# 3061MNNIC8 register map
File version: 1.0
Registers are 32-bit, access per field, reset 0x0 unless marked. A register's access mark holds for its fields unless they carry their own. Offsets are from the block's base; [hi:lo] are bit positions; {n}, {i} and the like mark numbered series.

## CAPM_COMM — CAPM_COMM peripheral interface
Base 0x14B03000
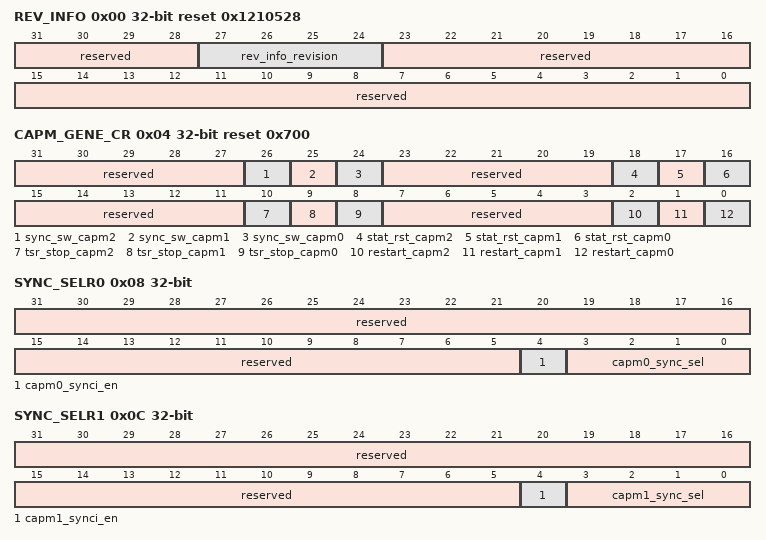
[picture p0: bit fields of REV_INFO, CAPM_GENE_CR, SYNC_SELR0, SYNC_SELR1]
0x00 REV_INFO ro reset 0x1210528 — Revision Information，版本信息寄存器。
  [31:28] reserved — 保留。
  [27:24] rev_info_revision — IP版本号。
  [23:0] reserved — 保留。
0x04 CAPM_GENE_CR reset 0x700 — Capture Module General Control Register，通用配置寄存器。
  [31:27] reserved ro — 时间戳计数器，可用于监视计数器状态。
  [26] sync_sw_capm2 rw write-1-clears — 触发CAPM2同步，对TSR置位，复位捕获序列。软件写1后自动清零。 0：不同步； 1：同步。写1后自动清零。
  [25] sync_sw_capm1 rw write-1-clears — 触发CAPM1同步，对TSR置位，复位捕获序列。软件写1后自动清零。 0：不同步； 1：同步。写1后自动清零。
  [24] sync_sw_capm0 rw write-1-clears — 触发CAPM0同步，对TSR置位，复位捕获序列。软件写1后自动清零。 0：不同步； 1：同步。写1后自动清零。
  [23:19] reserved ro — 保留。
  [18] stat_rst_capm2 rw write-1-clears — CAPM2工作状态复位，复位范围包括：TSR计数器；EAR计数器；捕获序列；TSR分频计数器；原始中断。 0：不复位； 1：复位。写1后自动清零。
  [17] stat_rst_capm1 rw write-1-clears — CAPM1工作状态复位，复位范围包括：TSR计数器、EAR计数器、捕获序列、TSR分频计数器、原始中断。 0：不复位； 1：复位。写1后自动清零。
  [16] stat_rst_capm0 rw write-1-clears — CAPM0工作状态复位，复位范围包括：TSR计数器、EAR计数器、捕获序列、TSR分频计数器、原始中断。 0：不复位； 1：复位。写1后自动清零。
  [15:11] reserved ro — 保留。
  [10] tsr_stop_capm2 rw — CAPM2 TSR暂停计数使能。 0：CAPM2 TSR继续计数； 1：CAPM2 TSR暂停计数。
  [9] tsr_stop_capm1 rw — CAPM1 TSR暂停计数使能。 0：CAPM2 TSR继续计数； 1：CAPM2 TSR暂停计数。
  [8] tsr_stop_capm0 rw — CAPM0 TSR暂停计数使能。 0：CAPM2 TSR继续计数； 1：CAPM2 TSR暂停计数。
  [7:3] reserved ro — 保留。
  [2] restart_capm2 rw write-1-clears — CAPM2开始一次新的单轮次捕获。 0：不开始； 1：开始。写1后自动清零。
  [1] restart_capm1 rw write-1-clears — CAPM1开始一次新的单轮次捕获。 0：不开始； 1：开始。写1后自动清零。
  [0] restart_capm0 rw write-1-clears — CAPM0开始一次新的单轮次捕获。 0：不开始； 1：开始。写1后自动清零。
0x08 SYNC_SELR0 — Sync Selection Register(for CAPM0)，CAPM0同步设置选择寄存器。
  [31:5] reserved ro — 保留。
  [4] capm0_synci_en rw — CAPM0 硬件，软件同步使能。 0：不使能； 1：使能。
  [3:0] capm0_sync_sel rw — CAPM0的硬件同步源选择。 0x0：无同步源； 0x1：APT0同步输出信号； 0x2：APT1同步输出信号； 0x3：APT2同步输出信号； 0x4：APT3同步输出信号； 其他：无同步源。
0x0C SYNC_SELR1 — Sync Selection Register(for CAPM1)，CAPM1同步设置选择寄存器。
  [31:5] reserved ro — 保留。
  [4] capm1_synci_en rw — CAPM1 硬件，软件同步使能。 0：不使能； 1：使能。
  [3:0] capm1_sync_sel rw — CAPM1的硬件同步源选择。 0x0：无同步源； 0x1：APT0同步输出信号； 0x2：APT1同步输出信号； 0x3：APT2同步输出信号； 0x4：APT3同步输出信号； 其他：无同步源。
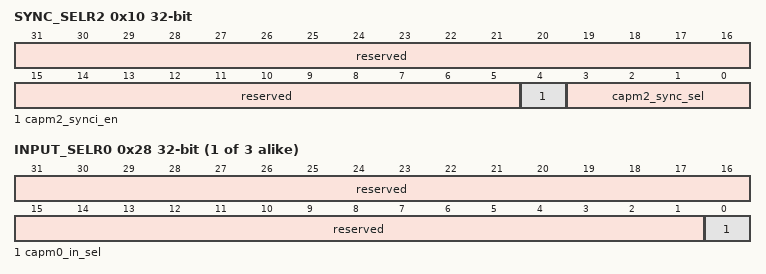
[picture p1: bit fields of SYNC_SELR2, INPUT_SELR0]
0x10 SYNC_SELR2 — Sync Selection Register(for CAPM2)，CAPM2同步设置选择寄存器。
  [31:5] reserved ro — 保留。
  [4] capm2_synci_en rw — CAPM2 硬件，软件同步使能。 0：不使能； 1：使能。
  [3:0] capm2_sync_sel rw — CAPM2的硬件同步源选择： 同capm0_sync_sel。
{0x28+4i} INPUT_SELR{i} (i=0..2) — Input Source Selection Register(for CAPM{i})，CAPM{i}输入源选择寄存器。
  [31:1] reserved ro — 保留。
  [0] capm{i}_in_sel rw — CAPM{i}输入源选择。 0：CAPM{i}_IN； 1：无。

## CMM — CMM peripheral interface
Base 0x10010000
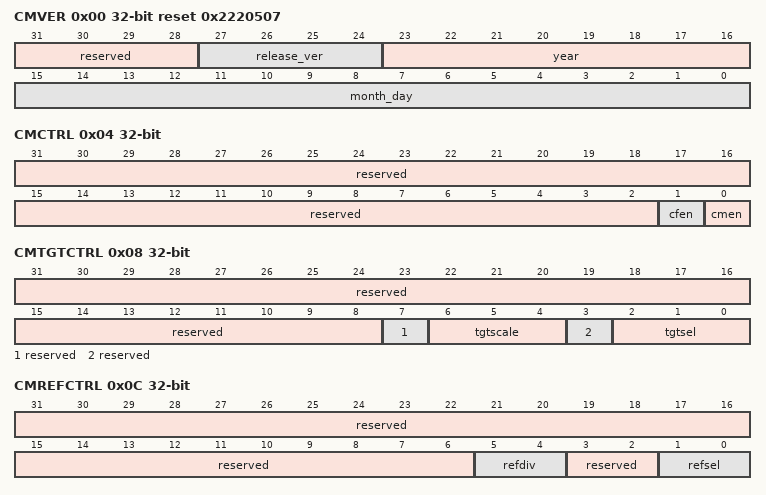
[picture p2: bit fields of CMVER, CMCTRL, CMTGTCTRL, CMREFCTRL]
0x00 CMVER ro reset 0x2220507 — CMM Version，CMM版本信息寄存器。
  [31:28] reserved — 保留。
  [27:24] release_ver — 版本信息。
  [23:16] year — 年。
  [15:0] month_day — 月日。
0x04 CMCTRL — CMM Control，CMM控制寄存器。
  [31:2] reserved ro — 保留。
  [1] cfen rw — CFD时钟失效检测使能。若使能该功能，当CMCNT大于cfwdoh时，clock_fail信号有效，自动将系统主频切换到clk_losc，同时输出到APT模块。若不使能该功能，cfwdoh无效，clock_fail信号无效。该功能受cmen控制。 0x0:不使能； 0x1:使能。
  [0] cmen rw — CMM 模块使能。 0x0:不使能； 0x1:使能。
0x08 CMTGTCTRL — CMM Target Clock Control，CMM目标时钟控制寄存器。
  [31:8] reserved ro — 保留。
  [7] reserved ro — 保留。
  [6:4] tgtscale rw — CMM 目标时钟分频系数，偶数倍占空比50%分频，CMM使用分频后的时钟作为被监控对象。 0x0:不分频； 0x1:32分频； 0x2:128分频； 0x3:1024分频； 0x4:8192分频； 其他:8192分频。
  [3] reserved ro — 保留。
  [2:0] tgtsel rw — CMM 工作目标时钟源选择。 0x0:目标时钟源0，clk_losc； 0x1:目标时钟源1，clk_hosc； 0x2:目标时钟源2，clk_tcxo； 0x3:目标时钟源3，clk_hs_sys； 0x4:目标时钟源4，暂无； 0x5:目标时钟源5，暂无； 0x6:目标时钟源6，暂无； 0x7:目标时钟源7，暂无。
0x0C CMREFCTRL — CMM Reference Clock Control，CMM参考时钟控制寄存器。
  [31:6] reserved ro — 保留。
  [5:4] refdiv rw — CMM 参考时钟分频系数，CMM使用分频后的时钟作为监控参考。 0x0：不分频； 0x1：4分频； 0x2：8分频； 0x3：32分频。
  [3:2] reserved ro — 保留。
  [1:0] refsel rw — CMM 工作参考时钟源选择。 0x0：参考时钟源0，clk_losc； 0x1：参考时钟源1，clk_hosc； 0x2：参考时钟源2，clk_tcxo； 0x3：参考时钟源3，clk_hs_sys。
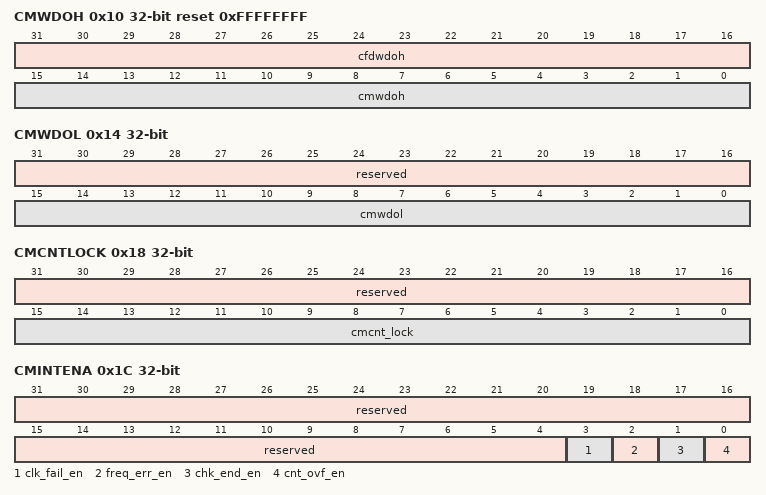
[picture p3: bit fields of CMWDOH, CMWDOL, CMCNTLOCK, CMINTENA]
0x10 CMWDOH rw reset 0xFFFFFFFF — CMM Check Window High，CMM检查窗口上限寄存器。
  [31:16] cfdwdoh — CMM 时钟失效检查窗口上界限，CMCNT大于该值说明目标时钟失效，产生clk_fail_raw原始中断。
  [15:0] cmwdoh — CMM 时钟频率错误检查窗口上界限，CMCNT大于该值说明频率错误，产生freq_err_raw原始中断。
0x14 CMWDOL — CMM Check Window Low，CMM检查窗口下限寄存器。
  [31:16] reserved ro — 保留。
  [15:0] cmwdol rw — CMM 时钟频率错误检查窗口下界限，CMCNT小于该值说明频率错误，产生freq_err_raw原始中断。
0x18 CMCNTLOCK ro — CMM Count Locked Value，CMM计数锁存值寄存器。
  [31:16] reserved — 保留。
  [15:0] cmcnt_lock — CMM 内部计数器计数锁存值。
0x1C CMINTENA — CMM Interrupt Enable，CMM中断使能寄存器。
  [31:4] reserved ro — 保留。
  [3] clk_fail_en rw — CMM 时钟失效中断使能。不使能时，即屏蔽相应的中断状态，不影响相应的原始中断。若全部不使能，CFD不会上报中断给CPU。 0x0：不使能； 0x1：使能。
  [2] freq_err_en rw — CMM 频率错误中断使能。不使能时，即屏蔽相应的中断状态，不影响相应的原始中断。若全部不使能，CMM不会上报中断给CPU。 0x0：不使能； 0x1：使能。
  [1] chk_end_en rw — CMM 检测结束中断使能。不使能时，即屏蔽相应的中断状态，不影响相应的原始中断。若全部不使能，CMM不会上报中断给CPU。 0x0：不使能； 0x1：使能。
  [0] cnt_ovf_en rw — CMM 计数溢出中断使能。不使能时，即屏蔽相应的中断状态，不影响相应的原始中断。若全部不使能，CMM不会上报中断给CPU。 0x0：不使能； 0x1：使能。
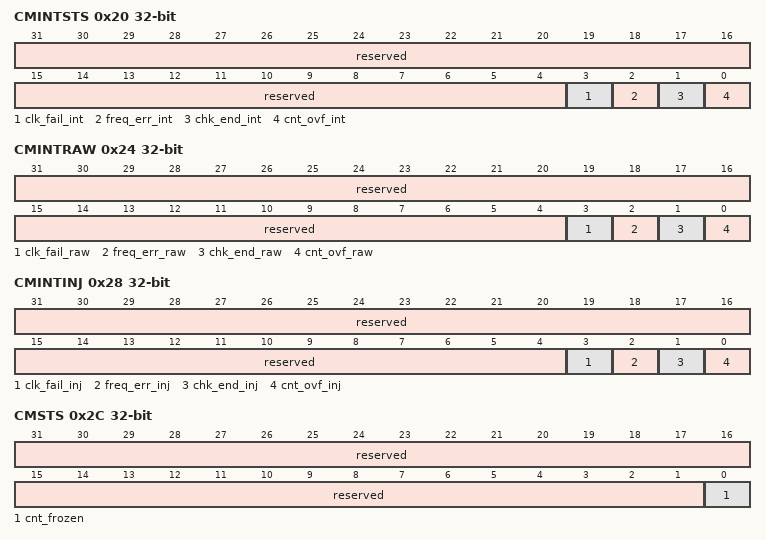
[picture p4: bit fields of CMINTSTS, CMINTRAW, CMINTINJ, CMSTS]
0x20 CMINTSTS ro — CMM Interrupt Status，CMM中断状态寄存器。
  [31:4] reserved — 保留。
  [3] clk_fail_int — CMM 时钟失效中断状态。 0x0：无中断； 0x1：有中断。
  [2] freq_err_int — CMM 频率错误中断状态。 0x0：无中断； 0x1：有中断。
  [1] chk_end_int — CMM 检测结束中断状态。 0x0：无中断； 0x1：有中断。
  [0] cnt_ovf_int — CMM 计数溢出中断状态。 0x0：无中断； 0x1：有中断。
0x24 CMINTRAW — CMM Raw Interrupt，CMM原始中断寄存器。
  [31:4] reserved ro — 保留。
  [3] clk_fail_raw rw write-clears — CMM 时钟失效原始中断。当cmen为1时，才可能产生此中断。 0x0：无原始中断； 0x1：有原始中断。写1清除中断。
  [2] freq_err_raw rw write-clears — CMM 频率错误原始中断。当cmen为1时，才可能产生此中断。 0x0：无原始中断； 0x1：有原始中断。写1清除中断。
  [1] chk_end_raw rw write-clears — CMM 检测结束中断原始中断。当cmen为1时，才可能产生此中断。 0x0：无原始中断； 0x1：有原始中断。写1清除中断。
  [0] cnt_ovf_raw rw write-clears — CMM 计数溢出中断原始中断。当cmen为1时，才可能产生此中断。 0x0：无原始中断； 0x1：有原始中断。写1清除中断。
0x28 CMINTINJ — CMM Interrupt Injection，CMM中断注入寄存器。
  [31:4] reserved ro — 保留。
  [3] clk_fail_inj rw write-1-clears — CMM 时钟失效中断注入。 0x0：不注入； 0x1：注入。写1后该位域自动清零。
  [2] freq_err_inj rw write-1-clears — CMM 频率错误中断注入。 0x0：不注入； 0x1：注入。写1后该位域自动清零。
  [1] chk_end_inj rw write-1-clears — CMM 检测结束中断注入。 0x0：不注入； 0x1：注入。写1后该位域自动清零。
  [0] cnt_ovf_inj rw write-1-clears — CMM 计数溢出中断注入。 0x0：不注入； 0x1：注入。写1后该位域自动清零。
0x2C CMSTS ro — CMM Status，CMM状态寄存器。
  [31:1] reserved — 保留。
  [0] cnt_frozen — CMCNT计数器是否被冻结。当CMCNT计数大于cfdwdoh时，CMCNT被冻结。清除clk_fail中断后，CMCNT被解冻。 0：CMCNT未被冻结； 1：CMCNT已被冻结。
